# PCIE0_DAT register map
Vendor: Texas Instruments
Registers are 32-bit, read-write, reset 0x0 unless marked. A register's access mark holds for its fields unless they carry their own. Offsets are as the file gives them; [hi:lo] are bit positions.

## PCIE0_DAT (part 5 of 6)
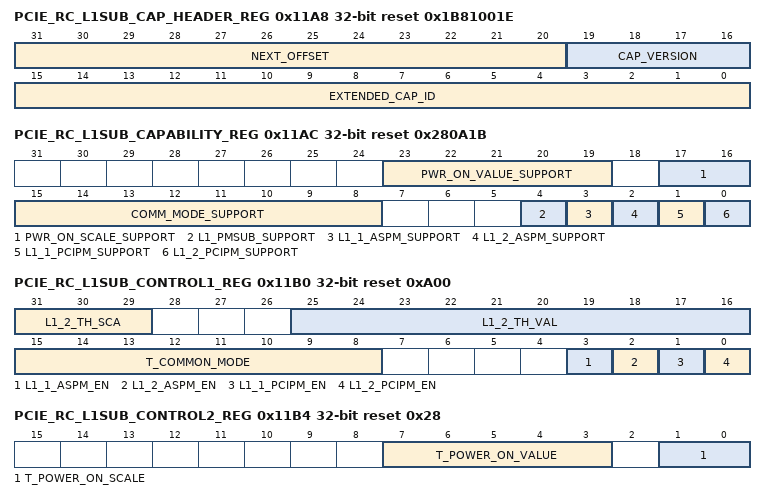
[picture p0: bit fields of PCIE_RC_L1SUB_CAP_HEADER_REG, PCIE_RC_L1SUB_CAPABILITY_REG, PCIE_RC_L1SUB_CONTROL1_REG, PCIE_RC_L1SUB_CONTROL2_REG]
0x11A8 PCIE_RC_L1SUB_CAP_HEADER_REG ro reset 0x1B81001E — L1 Substates Extended Capability Header. For a description of this standard PCIe register, see the PCI Express Specification.
  [31:20] NEXT_OFFSET — Next Capability Offset For a description of this standard PCIe register field, see the PCI Express Specification Note: The access attributes of this field are as follows: - Dbi: if [DBI_RO_WR_EN == 1] then R/W[sticky] else R[sticky] Note: This register field is sticky
  [19:16] CAP_VERSION — Capability Version For a description of this standard PCIe register field, see the PCI Express Specification Note: The access attributes of this field are as follows: - Dbi: if [DBI_RO_WR_EN == 1] then R/W[sticky] else R[sticky] Note: This register field is sticky
  [15:0] EXTENDED_CAP_ID — L1SUB Extended Capability ID For a description of this standard PCIe register field, see the PCI Express Specification Note: The access attributes of this field are as follows: - Dbi: if [DBI_RO_WR_EN == 1] then R/W[sticky] else R[sticky] Note: This register field is sticky
0x11AC PCIE_RC_L1SUB_CAPABILITY_REG access per field reset 0x280A1B — L1 Substates Capability Register. For a description of this standard PCIe register, see the PCI Express Specification.
  [23:19] PWR_ON_VALUE_SUPPORT rw — Port T Power On Value For a description of this standard PCIe register field, see the PCI Express Specification Note: The access attributes of this field are as follows: - Dbi: R/W
  [17:16] PWR_ON_SCALE_SUPPORT rw — Port T Power On Scale For a description of this standard PCIe register field, see the PCI Express Specification Note: The access attributes of this field are as follows: - Dbi: R/W
  [15:8] COMM_MODE_SUPPORT rw — Port Common Mode Restore Time For a description of this standard PCIe register field, see the PCI Express Specification Note: The access attributes of this field are as follows: - Dbi: R/W
  [4] L1_PMSUB_SUPPORT rw — L1 PM Substates ECN Supported For a description of this standard PCIe register field, see the PCI Express Specification Note: The access attributes of this field are as follows: - Dbi: R/W
  [3] L1_1_ASPM_SUPPORT rw — ASPM L11 Supported For a description of this standard PCIe register field, see the PCI Express Specification Note: The access attributes of this field are as follows: - Dbi: R/W
  [2] L1_2_ASPM_SUPPORT rw — ASPM L12 Supported For a description of this standard PCIe register field, see the PCI Express Specification Note: The access attributes of this field are as follows: - Dbi: R/W
  [1] L1_1_PCIPM_SUPPORT rw — PCI-PM L11 Supported For a description of this standard PCIe register field, see the PCI Express Specification Note: The access attributes of this field are as follows: - Dbi: R/W
  [0] L1_2_PCIPM_SUPPORT rw — PCI-PM L12 Supported For a description of this standard PCIe register field, see the PCI Express Specification Note: The access attributes of this field are as follows: - Dbi: R/W
0x11B0 PCIE_RC_L1SUB_CONTROL1_REG access per field reset 0xA00 — L1 Substates Control 1 Register. For a description of this standard PCIe register, see the PCI Express Specification.
  [31:29] L1_2_TH_SCA rw — LTR L12 Threshold Scale For a description of this standard PCIe register field, see the PCI Express Specification
  [25:16] L1_2_TH_VAL rw — LTR L12 Threshold Value For a description of this standard PCIe register field, see the PCI Express Specification
  [15:8] T_COMMON_MODE rw — Common Mode Restore Time For a description of this standard PCIe register field, see the PCI Express Specification Note: The access attributes of this field are as follows: - Dbi: R/W
  [3] L1_1_ASPM_EN rw — ASPM L11 Enable For a description of this standard PCIe register field, see the PCI Express Specification
  [2] L1_2_ASPM_EN rw — ASPM L12 Enable For a description of this standard PCIe register field, see the PCI Express Specification
  [1] L1_1_PCIPM_EN rw — PCI-PM L11 Enable For a description of this standard PCIe register field, see the PCI Express Specification
  [0] L1_2_PCIPM_EN rw — PCI-PM L12 Enable For a description of this standard PCIe register field, see the PCI Express Specification
0x11B4 PCIE_RC_L1SUB_CONTROL2_REG access per field reset 0x28 — L1 Substates Control 2 Register. For a description of this standard PCIe register, see the PCI Express Specification.
  [7:3] T_POWER_ON_VALUE rw — T Power On Value For a description of this standard PCIe register field, see the PCI Express Specification
  [1:0] T_POWER_ON_SCALE rw — T Power On Scale For a description of this standard PCIe register field, see the PCI Express Specification
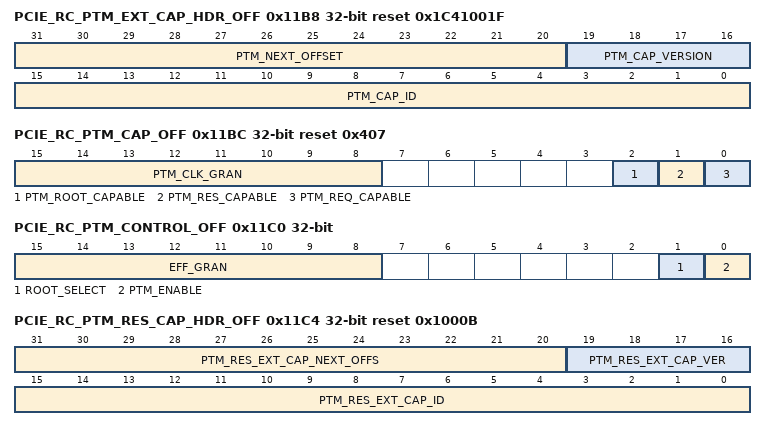
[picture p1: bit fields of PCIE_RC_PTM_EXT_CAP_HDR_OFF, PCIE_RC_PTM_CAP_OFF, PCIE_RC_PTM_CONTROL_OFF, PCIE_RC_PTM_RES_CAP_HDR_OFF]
0x11B8 PCIE_RC_PTM_EXT_CAP_HDR_OFF ro reset 0x1C41001F — Precision Time Measurement Capability Header. For a description of this standard PCIe register, see the PCI Express Specification.
  [31:20] PTM_NEXT_OFFSET — Precision Time Measurement PCI Express Extended Capability Next Offset For a description of this standard PCIe register, see the PCI Express Specification Note: The access attributes of this field are as follows: - Dbi: if [DBI_RO_WR_EN == 1] then R/W[sticky] else R[sticky] Note: This register field is sticky
  [19:16] PTM_CAP_VERSION — Precision Time Measurement PCI Express Extended Capability Version For a description of this standard PCIe register, see the PCI Express Specification Note: The access attributes of this field are as follows: - Dbi: if [DBI_RO_WR_EN == 1] then R/W[sticky] else R[sticky] Note: This register field is sticky
  [15:0] PTM_CAP_ID — Precision Time Measurement PCI Express Extended Capability ID For a description of this standard PCIe register, see the PCI Express Specification Note: The access attributes of this field are as follows: - Dbi: if [DBI_RO_WR_EN == 1] then R/W[sticky] else R[sticky] Note: This register field is sticky
0x11BC PCIE_RC_PTM_CAP_OFF ro reset 0x407 — PTM Capability Register. For a description of this standard PCIe register, see the PCI Express Specification.
  [15:8] PTM_CLK_GRAN — PTM Local Clock Granularity For a description of this standard PCIe register, see the PCI Express Specification Note: The access attributes of this field are as follows: - Dbi: if [DBI_RO_WR_EN == 1] then R/W[sticky] else R[sticky]
  [2] PTM_ROOT_CAPABLE — PTM Root Capable For a description of this standard PCIe register, see the PCI Express Specification Note: The access attributes of this field are as follows: - Dbi: if [DBI_RO_WR_EN == 1] then R/W[sticky] else R[sticky] Note: This register field is sticky
  [1] PTM_RES_CAPABLE — PTM Responder Capable For a description of this standard PCIe register, see the PCI Express Specification Note: The access attributes of this field are as follows: - Dbi: if [DBI_RO_WR_EN == 1] then R/W[sticky] else R[sticky] Note: This register field is sticky
  [0] PTM_REQ_CAPABLE — PTM Requester Capable For a description of this standard PCIe register, see the PCI Express Specification Note: The access attributes of this field are as follows: - Dbi: if [DBI_RO_WR_EN == 1] then R/W[sticky] else R[sticky] Note: This register field is sticky
0x11C0 PCIE_RC_PTM_CONTROL_OFF access per field — PTM Control Register. For a description of this standard PCIe register, see the PCI Express Specification.
  [15:8] EFF_GRAN ro — PTM Effective Granularity For a description of this standard PCIe register, see the PCI Express Specification Note: The access attributes of this field are as follows: - Dbi: HWINIT
  [1] ROOT_SELECT ro — PTM Root Select When set this Time Source is the PTM Root For a description of this standard PCIe register, see the PCI Express Specification Note: The access attributes of this field are as follows: - Dbi: HWINIT
  [0] PTM_ENABLE rw — PTM Enable When set, this function is permitted to participate in the PTM mechanism For a description of this standard PCIe register, see the PCI Express Specification
0x11C4 PCIE_RC_PTM_RES_CAP_HDR_OFF ro reset 0x1000B — Precision Time Measurement Responder Capability Header (VSEC).
  [31:20] PTM_RES_EXT_CAP_NEXT_OFFS — Precision Time Measurement Responder VSEC Next Pointer Note: The access attributes of this field are as follows: - Dbi: if [DBI_RO_WR_EN == 1] then R/W[sticky] else R[sticky] Note: This register field is sticky
  [19:16] PTM_RES_EXT_CAP_VER — Precision Time Measurement Responder VSEC Version Note: The access attributes of this field are as follows: - Dbi: if [DBI_RO_WR_EN == 1] then R/W[sticky] else R[sticky] Note: This register field is sticky
  [15:0] PTM_RES_EXT_CAP_ID — Precision Time Measurement Responder VSEC ID Note: The access attributes of this field are as follows: - Dbi: if [DBI_RO_WR_EN == 1] then R/W[sticky] else R[sticky] Note: This register field is sticky
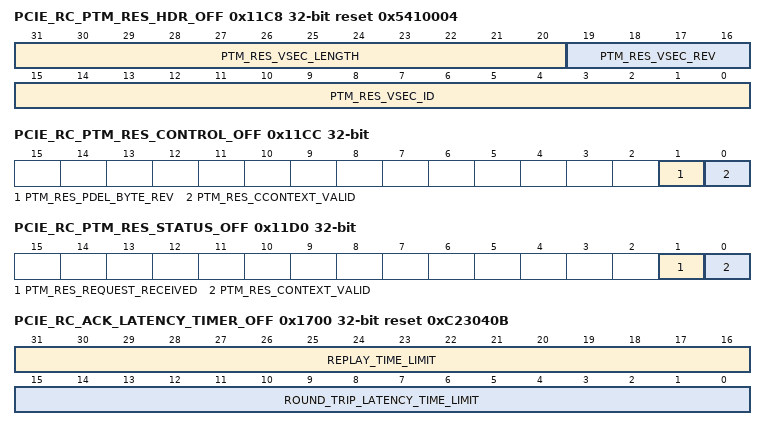
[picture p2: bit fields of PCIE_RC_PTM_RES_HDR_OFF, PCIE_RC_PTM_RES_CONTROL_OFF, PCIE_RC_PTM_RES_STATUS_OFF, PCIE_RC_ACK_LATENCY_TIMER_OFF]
0x11C8 PCIE_RC_PTM_RES_HDR_OFF ro reset 0x5410004 — Precision Time Measurement Responder Vendor Specific Header. .
  [31:20] PTM_RES_VSEC_LENGTH — PTM Responder VSEC Length Note: The access attributes of this field are as follows: - Dbi: if [DBI_RO_WR_EN == 1] then R/W[sticky] else R[sticky] Note: This register field is sticky
  [19:16] PTM_RES_VSEC_REV — PTM Responder VSEC Revision Note: The access attributes of this field are as follows: - Dbi: if [DBI_RO_WR_EN == 1] then R/W[sticky] else R[sticky] Note: This register field is sticky
  [15:0] PTM_RES_VSEC_ID — PTM Responder VSEC ID Note: The access attributes of this field are as follows: - Dbi: if [DBI_RO_WR_EN == 1] then R/W[sticky] else R[sticky] Note: This register field is sticky
0x11CC PCIE_RC_PTM_RES_CONTROL_OFF access per field — PTM Responder Control Register. .
  [1] PTM_RES_PDEL_BYTE_REV rw — PTM Requester Propagation Delay Byte Reversal - Reverse the order of bytes in the PTM Propagation Delay data word of the PTM ResponseD Message, for compatibility with previous revisions. Note: This register field is sticky.
  [0] PTM_RES_CCONTEXT_VALID ro — PTM Responder Control Context Valid - PTM Local Timing is valid This bit is set over the DBI A speed change or aux_clk_active will set this bit low Note: The access attributes of this field are as follows: - Dbi: if [DBI_RO_WR_EN == 1] then R/W[sticky] else R[sticky] Note: This register field is sticky
0x11D0 PCIE_RC_PTM_RES_STATUS_OFF ro — PTM Responder Status Register. .
  [1] PTM_RES_REQUEST_RECEIVED — PTM 1st Request Received - PTM Responder has received the first PTM Request Message Upon receipt of a second PTM Request Message a ResponseD message with timing information will be sent from the Responder, if the context is valid If the context is invalid a Response message will be sent instead Note: This register field is sticky
  [0] PTM_RES_CONTEXT_VALID — PTM Responder Status Context Valid - PTM Local Timing Context is Valid Value set from upstream port Requester in a Switch Shadows the same in the control register in all other products Note: This register field is sticky
0x11D4 PCIE_RC_PTM_RES_LOCAL_LSB_OFF ro — PTM Responder Local Clock LSB. .
  [31:0] PTM_RES_LOCAL_LSB — PTM Responder Local Clock LSB - Lower 32 bits of local timer value Note: The access attributes of this field are as follows: - Dbi: if [DBI_RO_WR_EN == 1] then R/W[sticky] else R[sticky] Note: This register field is sticky
0x11D8 PCIE_RC_PTM_RES_LOCAL_MSB_OFF ro — PTM Responder Local Clock MSB. .
  [31:0] PTM_RES_LOCAL_MSB — PTM Responder Local Clock MSB - Upper 32 bits of local timer value Note: The access attributes of this field are as follows: - Dbi: if [DBI_RO_WR_EN == 1] then R/W[sticky] else R[sticky] Note: This register field is sticky
0x11DC PCIE_RC_PTM_RES_T2_LSB_OFF ro — PTM Responder T2 Timestamp LSB. .
  [31:0] PTM_RES_T2_LSB — PTM Responder T2 Timestamp LSB - Lower 32 bits of the T2 Timestamp value Note: This register field is sticky
0x11E0 PCIE_RC_PTM_RES_T2_MSB_OFF ro — PTM Responder T2 Timestamp MSB. .
  [31:0] PTM_RES_T2_MSB — PTM Responder T2 Timestamp MSB - Upper 32 bits of the T2 Timestamp value Note: This register field is sticky
0x11E4 PCIE_RC_PTM_RES_T2P_LSB_OFF ro — PTM Responder T2 Previous Timestamp LSB. .
  [31:0] PTM_RES_T2P_LSB — PTM Responder T2 Previous Timestamp LSB - Lower 32 bits of the previously stored T2 Timestamp value Note: This register field is sticky
0x11E8 PCIE_RC_PTM_RES_T2P_MSB_OFF ro — PTM Responder T2 Previous Timestamp MSB. .
  [31:0] PTM_RES_T2P_MSB — PTM Responder T2 Previous Timestamp MSB - Upper 32 bits of the previously stored T2 Timestamp value Note: This register field is sticky
0x11EC PCIE_RC_PTM_RES_T3_LSB_OFF ro — PTM Responder T3 Timestamp LSB. .
  [31:0] PTM_RES_T3_LSB — PTM Responder T3 Timestamp LSB - Lower 32 bits of the T3 Timestamp value Note: This register field is sticky
0x11F0 PCIE_RC_PTM_RES_T3_MSB_OFF ro — PTM Responder T3 Timestamp MSB. .
  [31:0] PTM_RES_T3_MSB — PTM Responder T3 Timestamp MSB - Upper 32 bits of the T2 Timestamp value Note: This register field is sticky
0x11F4 PCIE_RC_PTM_RES_T3P_LSB_OFF ro — PTM Responder T3 Previous Timestamp LSB. .
  [31:0] PTM_RES_T3P_LSB — PTM Responder T3 Previous Timestamp LSB - Lower 32 bits of the previously stored T3 Timestamp value Note: This register field is sticky
0x11F8 PCIE_RC_PTM_RES_T3P_MSB_OFF ro — PTM Responder T3 Previous Timestamp MSB. .
  [31:0] PTM_RES_T3P_MSB — PTM Responder T3 Previous Timestamp MSB - Upper 32 bits of the previously stored T3 Timestamp value Note: This register field is sticky
0x11FC PCIE_RC_PTM_RES_TX_LATENCY_OFF access per field reset 0x14 — PTM Responder TX Latency. .
  [11:0] PTM_RES_TX_LATENCY rw — PTM Responder TX Latency - Responder Transmit path latency [12 bit wide] Note: This register field is sticky
0x1200 PCIE_RC_PTM_RES_RX_LATENCY_OFF access per field reset 0x36 — PTM Responder RX Latency. .
  [11:0] PTM_RES_RX_LATENCY rw — PTM Responder RX Latency - Responder Receive path latency [12 bit wide] Note: This register field is sticky
0x1700 PCIE_RC_ACK_LATENCY_TIMER_OFF reset 0xC23040B — Ack Latency Timer and Replay Timer Register.
  [31:16] REPLAY_TIME_LIMIT — Replay Timer Limit The replay timer expires when it reaches this limit The controller initiates a replay upon reception of a NAK or when the replay timer expires You can modify the effective timer limit with the TIMER_MOD_REPLAY_TIMER field of thePCIE_RC_TIMER_CTRL_MAX_FUNC_NUM_OFF register After reset, the controller updates the default according to the Negotiated Link Width, Max_Payload_Size, and speed The value is determined from Tables 3-4, 3-5, and 3-6 of the PCIe 30 specification If there is a change in the payload size or link speed, the controller will override any value that you have written to this register field, and reset the field back to the specification-defined value It will not change the value in the TIMER_MOD_REPLAY_TIMER field of the PCIE_RC_TIMER_CTRL_MAX_FUNC_NUM_OFF register
  [15:0] ROUND_TRIP_LATENCY_TIME_LIMIT — Ack Latency Timer Limit The Ack latency timer expires when it reaches this limit You can modify the effective timer limit with the TIMER_MOD_ACK_NAK field of thePCIE_RC_TIMER_CTRL_MAX_FUNC_NUM_OFF register After reset, the controller updates the default according to the Negotiated Link Width, Max_Payload_Size, and speed The value is determined from Tables 3-7, 3-8, and 3-9 of the PCIe 30 specification The limit must reflect the round trip latency from requester to completer If there is a change in the payload size or link width, the controller will override any value that you have written to this register field, and reset the field back to the specification-defined value It will not change the value in the TIMER_MOD_ACK_NAK field of the PCIE_RC_TIMER_CTRL_MAX_FUNC_NUM_OFF register
0x1704 PCIE_RC_VENDOR_SPEC_DLLP_OFF reset 0xFFFFFFFF — Vendor Specific DLLP Register.
  [31:0] VENDOR_SPEC_DLLP — Vendor Specific DLLP Register Used to send a specific PCI Express DLLP Your application writes the 8-bit DLLP Type and 24-bits of Payload data into this register, then sets the field VENDOR_SPECIFIC_DLLP_REQ of
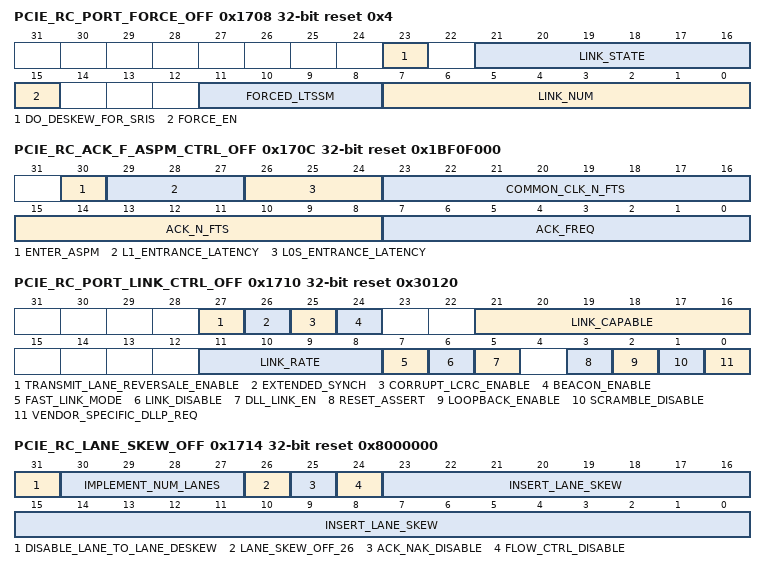
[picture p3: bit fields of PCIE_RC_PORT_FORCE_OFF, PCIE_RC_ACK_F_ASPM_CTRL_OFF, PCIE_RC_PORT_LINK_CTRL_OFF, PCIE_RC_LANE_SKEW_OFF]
0x1708 PCIE_RC_PORT_FORCE_OFF access not given reset 0x4 — Port Force Link Register.
  [23] DO_DESKEW_FOR_SRIS rw — Use the transitions from TS2 to Logical Idle Symbol, SKP OS to Logical Idle Symbol, and FTS Sequence to SKP OS to do deskew for SRIS instead of using received SKP OS if DO_DESKEW_FOR_SRIS is set to 1 Note: This register field is sticky
  [21:16] LINK_STATE rw — Forced LTSSM State The LTSSM state that the controller is forced to when you set the FORCE_EN bit [Force Link] LTSSM state encoding is defined by the lts_state variable in workspace/src/Layer1/smlh_ltssmv Note: This register field is sticky
  [15] FORCE_EN — Force Link The controller supports a testing and debug capability to allow your software to force the LTSSM state machine into a specific state, and to force the controller to transmit a specific Link Command Asserting this bit triggers the following actions: - Forces the LTSSM to the state specified by the Forced LTSSM State field - Forces the controller to transmit the command specified by the Forced Link Command field This is a self-clearing register field Reading from this register field always returns a '0' (access RW1C)
  [11:8] FORCED_LTSSM rw — Forced Link Command The link command that the controller is forced to transmit when you set FORCE_EN bit [Force Link] Link command encoding is defined by the ltssm_cmd variable in workspace/src/Layer1/smlh_ltssmv Note: This register field is sticky
  [7:0] LINK_NUM rw — Link Number Not used for endpoint Not used for M-PCIe Note: This register field is sticky
0x170C PCIE_RC_ACK_F_ASPM_CTRL_OFF access per field reset 0x1BF0F000 — Ack Frequency and L0-L1 ASPM Control Register.
  [30] ENTER_ASPM rw — ASPM L1 Entry Control - 1: Core enters ASPM L1 after a period in which it has been idle - 0: Core enters ASPM L1 only after idle period during which both receive and transmit are in L0s Note: This register field is sticky
  [29:27] L1_ENTRANCE_LATENCY rw — L1 Entrance Latency Value range is: - 000: 1 us - 001: 2 us - 010: 4 us - 011: 8 us - 100: 16 us - 101: 32 us - 110 or 111: 64 us Note: Programming this timer with a value greater that 32us has no effect unless extended sync is used, or all of the credits are infinite Note: This register field is sticky
  [26:24] L0S_ENTRANCE_LATENCY rw — L0s Entrance Latency Values correspond to: - 000: 1 us - 001: 2 us - 010: 3 us - 011: 4 us - 100: 5 us - 101: 6 us - 110 or 111: 7 us This field is applicable to STALL while in L0 for M-PCIe Note: This register field is sticky
  [23:16] COMMON_CLK_N_FTS ro — Common Clock N_FTS This is the N_FTS when common clock is used The number of Fast Training Sequence ordered sets to be transmitted when transitioning from L0s to L0 The maximum number of FTS ordered-sets that a component can request is 255 This field is only writable [sticky] when all of the following configuration parameter equations are true: - CX_NFTS !=CX_COMM_NFTS - DEFAULT_L0S_EXIT_LATENCY !=DEFAULT_COMM_L0S_EXIT_LATENCY - DEFAULT_L1_EXIT_LATENCY !=DEFAULT_COMM_L1_EXIT_LATENCY The controller does not support a value of zero a value of zero can cause the LTSSM to go into the recovery state when exiting from L0s This field is reserved [fixed to '0'] for M-PCIe Note: The access attributes of this field are as follows: - Dbi: R
  [15:8] ACK_N_FTS rw — N_FTS The number of Fast Training Sequence ordered sets to be transmitted when transitioning from L0s to L0 The maximum number of FTS ordered-sets that a component can request is 255 The controller does not support a value of zero a value of zero can cause the LTSSM to go into the recovery state when exiting from L0s This field is reserved [fixed to '0'] for M-PCIe Note: This register field is sticky
  [7:0] ACK_FREQ rw — Ack Frequency The controller accumulates the number of pending ACKs specified here [up to 255] before sending an ACK DLLP - 0: Indicates that this Ack frequency control feature is turned off The controller schedules a low-priority ACK DLLP for every TLP that it receives - 1- 255: Indicates that the controller will schedule a high-priority ACK after receiving this number of TLPs It might schedule the ACK before receiving this number of TLPs, but never later For a typical system, you do not have to modify the default setting Note: This register field is sticky
0x1710 PCIE_RC_PORT_LINK_CTRL_OFF access not given reset 0x30120 — Port Link Control Register.
  [27] TRANSMIT_LANE_REVERSALE_ENABLE rw — TRANSMIT_LANE_REVERSALE_ENABLE is an internally reserved field Do not use Note: This register field is sticky
  [26] EXTENDED_SYNCH rw — EXTENDED_SYNCH is an internally reserved field Do not use Note: This register field is sticky
  [25] CORRUPT_LCRC_ENABLE rw — CORRUPT_LCRC_ENABLE is an internally reserved field Do not use Note: This register field is sticky
  [24] BEACON_ENABLE rw — BEACON_ENABLE is an internally reserved field Do not use Note: This register field is sticky
  [21:16] LINK_CAPABLE rw — Link Mode Enable Sets the number of lanes in the link that you want to connect to the link partner When you have unused lanes in your system, then you must change the value in this register to reflect the number of lanes You must also change the value in the 'Predetermined Number of Lanes' field of the 'Link Width and Speed Change Control Register' - 000001: x 1 - 000011: x 2 - 000111: x 4 - 001111: x 8 - 011111: x 16 - 111111: x32 [not supported] This field is reserved [fixed to '0'] for M-PCIe Note: This register field is sticky
  [11:8] LINK_RATE rw — LINK_RATE is an internally reserved field Do not use Note: This register field is sticky
  [7] FAST_LINK_MODE rw — Fast Link Mode Sets all internal LTSSM millisecond timers to Fast Mode for speeding up simulation Forces the LTSSM training [link initialization] to use shorter time-outs and to link up faster The default scaling factor can be changed using the DEFAULT_FAST_LINK_SCALING_FACTOR parameter or through the FAST_LINK_SCALING_FACTOR field in the
  [6] LINK_DISABLE rw — LINK_DISABLE is an internally reserved field Do not use Note: This register field is sticky
  [5] DLL_LINK_EN rw — DLL Link Enable Enables link initialization When DLL Link Enable =0, the controller does not transmit InitFC DLLPs and does not establish a link Note: This register field is sticky
  [3] RESET_ASSERT rw — Reset Assert Triggers a recovery and forces the LTSSM to the hot reset state [downstream port only] Note: This register field is sticky
  [2] LOOPBACK_ENABLE rw — Loopback Enable Turns on loopback For M-PCIe, to force the master to enter Digital Loopback mode, you must set this field to '1' during Configurationstart state[initial discovery/configuration] M-PCIe doesn't support loopback mode from L0 state - only from Configurationstart Note: This register field is sticky
  [1] SCRAMBLE_DISABLE rw — Scramble Disable Turns off data scrambling Note: This register field is sticky
  [0] VENDOR_SPECIFIC_DLLP_REQ — Vendor Specific DLLP Request When software writes a '1' to this bit, the controller transmits the DLLP contained in the VENDOR_SPEC_DLLP field of (access RW1C)
0x1714 PCIE_RC_LANE_SKEW_OFF reset 0x8000000 — Lane Skew Register.
  [31] DISABLE_LANE_TO_LANE_DESKEW — Disable Lane-to-Lane Deskew Causes the controller to disable the internal Lane-to-Lane deskew logic Note: This register field is sticky
  [30:27] IMPLEMENT_NUM_LANES — Implementation-specific Number of Lanes Set the implementation-specific number of lanes Allowed values are: - 4'b 0000: 1 lane - 4'b 0001: 2 lanes - 4'b 0011: 4 lanes - 4'b 0111: 8 lanes - 4'b 1111: 16 lanes The number of lanes to be used when in Loopback Master The number of lanes programmed must be equal to or less than the valid number of lanes set in LINK_CAPABLE field You must configure this field before initiating Loopback by writing in the LOOPBACK_ENABLE field The controller will transition from LoopbackEntry to LoopbackActive after receiving two consecutive TS1 Ordered Sets with the Loopback bit asserted on the implementation specific number of lanes configured in this field Note: This register field is sticky
  [26] LANE_SKEW_OFF_26 — Reserved Read/Write regsiter for future use Note: This register field is sticky
  [25] ACK_NAK_DISABLE — Ack/Nak Disable Prevents the controller from sending ACK and NAK DLLPs Note: This register field is sticky
  [24] FLOW_CTRL_DISABLE — Flow Control Disable Prevents the controller from sending FC DLLPs Note: This register field is sticky
  [23:0] INSERT_LANE_SKEW — Insert Lane Skew for Transmit [not supported for x16] Optional feature that causes the controller to insert skew between Lanes for test purposes There are three bits per Lane The value is in units of one symbol time For example, the value 010b for a Lane forces a skew of two symbol times for that Lane The maximum skew value for any Lane is 5 symbol times Note: This register field is sticky
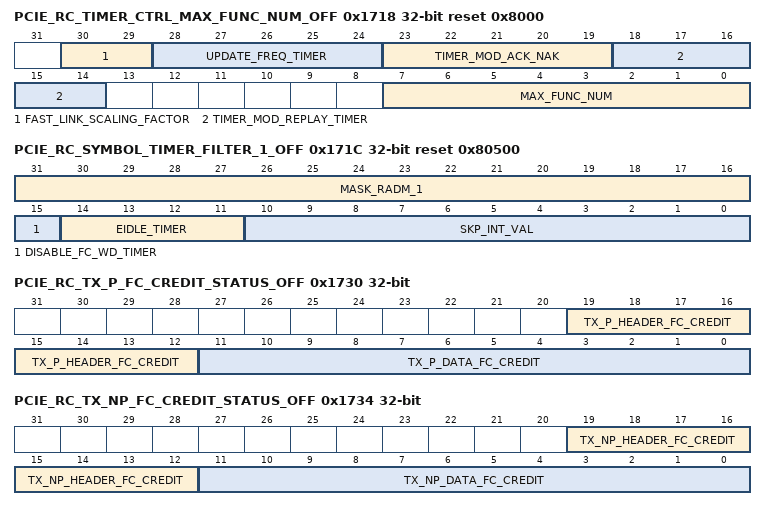
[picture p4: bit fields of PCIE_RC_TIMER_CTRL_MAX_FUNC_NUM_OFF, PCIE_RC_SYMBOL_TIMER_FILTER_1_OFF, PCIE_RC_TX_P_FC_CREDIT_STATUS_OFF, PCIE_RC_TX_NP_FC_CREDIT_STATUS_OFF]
0x1718 PCIE_RC_TIMER_CTRL_MAX_FUNC_NUM_OFF access per field reset 0x8000 — Timer Control and Max Function Number Register.
  [30:29] FAST_LINK_SCALING_FACTOR rw — Fast Link Timer Scaling Factor Sets the scaling factor of LTSSM timer when FAST_LINK_MODE field inPCIE_RC_PORT_LINK_CTRL_OFF is set to '1' - 0: Scaling Factor is 1024 [1ms is 1us] - 1: Scaling Factor is 256 [1ms is 4us] - 2: Scaling Factor is 64 [1ms is 16us] - 3: Scaling Factor is 16 [1ms is 64us] Default is set by the hidden configuration parameter DEFAULT_FAST_LINK_SCALING_FACTOR which defaults to '0' Not used for M-PCIe Note: This register field is sticky
  [28:24] UPDATE_FREQ_TIMER rw — UPDATE_FREQ_TIMER is an internally reserved field Do not use Note: This register field is sticky
  [23:19] TIMER_MOD_ACK_NAK rw — Ack Latency Timer Modifier Increases the timer value for the Ack latency timer in increments of 64 clock cycles A value of '0' represents no modification to the timer value For more details, see the ROUND_TRIP_LATENCY_TIME_LIMIT field of the
  [18:14] TIMER_MOD_REPLAY_TIMER rw — Replay Timer Limit Modifier Increases the time-out value for the replay timer in increments of 64 clock cycles at Gen1 or Gen2 speed, and in increments of 256 clock cycles at Gen3 speed A value of '0' represents no modification to the timer limit For more details, see the REPLAY_TIME_LIMIT field of the
  [7:0] MAX_FUNC_NUM rw — Maximum function number that can be used in a request Configuration requests targeted at function numbers above this value are returned with UR [unsupported request] Note: This register field is sticky
0x171C PCIE_RC_SYMBOL_TIMER_FILTER_1_OFF reset 0x80500 — Symbol Timer Register and Filter Mask 1 Register. The Filter Mask 1 Register modifies the RADM filtering and error handling rules. In each case, '0' applies the associated filtering rule and '1' masks the associated filtering rule.
  [31:16] MASK_RADM_1 — Filter Mask 1. The Filter Mask 1 Register modifies the RADM filtering and error handling rules. In each case, '0' applies the associated filtering rule and '1' masks the associated filtering rule. [31]: CX_FLT_MASK_RC_CFG_DISCARD 0: For RADM RC filter to not allow CFG transaction being received 1: For RADM RC filter to allow CFG transaction being received [30]: CX_FLT_MASK_RC_IO_DISCARD 0: For RADM RC filter to not allow IO transaction being received 1: For RADM RC filter to allow IO transaction being received [29]: CX_FLT_MASK_MSG_DROP 0: Drop MSG TLP [except for Vendor MSG]. Send decoded message on the SII. 1: Do not Drop MSG [except for Vendor MSG]. Send message TLPs to your application on TRGT1 and send decoded message on the SII. The default for this bit is the inverse of FLT_DROP_MSG. That is, if FLT_DROP_MSG = 1, then the default of this bit is '0' [drop message TLPs]. This bit only controls message TLPs other than Vendor MSGs. Vendor MSGs are controlled by Filter Mask Register 2, bits [1:0]. The controller never passes ATS Invalidate messages to the SII interface regardless of this filter rule setting. The controller passes all ATS Invalidate messages to TRGT1 [or AXI bridge master], as they are too big for the SII. [28]: CX_FLT_MASK_CPL_ECRC_DISCARD Only used when completion queue is advertised with infinite credits and is in store-and-forward mode. 0: Discard completions with ECRC errors 1: Allow completions with ECRC errors to be passed up Reserved field for SW. [27]: CX_FLT_MASK_ECRC_DISCARD 0: Discard TLPs with ECRC errors 1: Allow TLPs with ECRC errors to be passed up [26]: CX_FLT_MASK_CPL_LEN_MATCH 0: Enforce length match for completions; a violation results in cpl_abort, and possibly AER of unexp_cpl_err 1: MASK length match for completions [25]: CX_FLT_MASK_CPL_ATTR_MATCH 0: Enforce attribute match for completions; a violation results in a malformed TLP error, and possibly AER of unexp_cpl_err, cpl_rcvd_ur, cpl_rcvd_ca 1: Mask attribute match for completions [24]: CX_FLT_MASK_CPL_TC_MATCH 0: Enforce Traffic Class match for completions; a violation results in a malformed TLP error, and possibly AER of unexp_cpl_err, cpl_rcvd_ur, cpl_rcvd_ca 1: Mask Traffic Class match for completions [23]: CX_FLT_MASK_CPL_FUNC_MATCH 0: Enforce function match for completions; a violation results in cpl_abort, and possibly AER of unexp_cpl_err, cpl_rcvd_ur, cpl_rcvd_ca 1: Mask function match for completions [22]: CX_FLT_MASK_CPL_REQID_MATCH 0: Enforce Req Id match for completions; a violation result in cpl_abort, and possibly AER of unexp_cpl_err, cpl_rcvd_ur, cpl_rcvd_ca 1: Mask Req Id match for completions [21]: CX_FLT_MASK_CPL_TAGERR_MATCH 0: Enforce Tag Error Rules for completions; a violation result in cpl_abort, and possibly AER of unexp_cpl_err, cpl_rcvd_ur, cpl_rcvd_cа 1: Mask Tag Error Rules for completions [20]: CX_FLT_MASK_LOCKED_RD_AS_UR 0: Treat locked Read TLPs as UR for EP; Supported for RC 1: Treat locked Read TLPs as Supported for EP; UR for RC [19]: CX_FLT_MASK_CFG_TYPE1_RE_AS_UR 0: Treat CFG type1 TLPs as UR for EP; Supported for RC 1: Treat CFG type1 TLPs as Supported for EP; UR for RC When CX_SRIOV_ENABLE is set then this bit is set to allow the filter to process Type 1 Config requests, if the EP consumes more than one bus number. [18]: CX_FLT_MASK_UR_OUTSIDE_BAR 0: Treat out-of-bar TLPs as UR 1: Do not treat out-of-bar TLPs as UR [17]: CX_FLT_MASK_UR_POIS 0: Treat poisoned request TLPs as UR 1: Do not treat poisoned request TLPs as UR The native controller always passes poisoned completions to your application except when you are using the DMA read channel. [16]: CX_FLT_MASK_UR_FUNC_MISMATCH 0: Treat Function MisMatched TLPs as UR 1: Do not treat Function MisMatched TLPs as UR Note: This register field is sticky.
  [15] DISABLE_FC_WD_TIMER — Disable FC Watchdog Timer. Note: This register field is sticky.
  [14:11] EIDLE_TIMER — EIDLE_TIMER is an internally reserved field. Do not use. Note: This register field is sticky.
  [10:0] SKP_INT_VAL — SKP Interval Value. The number of symbol times to wait between transmitting SKP ordered sets. Note that the controller actually waits the number of symbol times in this register plus 1 between transmitting SKP ordered sets. Your application must program this register accordingly. For example, if 1536 were programmed into this register [in a 250 MHz controller], then the controller actually transmits SKP ordered sets once every 1537 symbol times. The value programmed to this register is actually clock ticks and not symbol times. In a 125 MHz controller, programming the value programmed to this register should be scaled down by a factor of 2 [because one clock tick = two symbol times in this case]. Note: This value is not used at Gen3 speed. The skip interval is hardcoded to 370 blocks For M-PCIe configurations, if the 2K_PPM_DISABLED field in the M-PCIe Configuration Attribute is changed, then this field is changed automatically as follows: 2K_PPM_DISABLED = 1: 1280/CX_NB 2K_PPM_DISABLED = 0: 228/CX_NB You need to set this field again, if necessary, when 2K_PPM_DISABLED is changed. Note: This register field is sticky.
0x1720 PCIE_RC_FILTER_MASK_2_OFF — Filter Mask 2 Register. This register modifies the RADM filtering and error handling rules. In each case, '0' applies the associated filtering rule and '1' masks the associated filtering rule.
  [31:0] MASK_RADM_2 — Filter Mask 2. This field modifies the RADM filtering and error handling rules. In each case, '0' applies the associated filtering rule and '1' masks the associated filtering rule.
0x1724 PCIE_RC_AMBA_MUL_OB_DECOMP_NP_SUB_REQ_CTRL_OFF access per field reset 0x1 — AMBA Multiple Outbound Decomposed NP SubRequests Control Register.
  [0] OB_RD_SPLIT_BURST_EN rw — Enable AMBA Multiple Outbound Decomposed NP SubRequests This bit when set to '0' disables the possibility of having multiple outstanding non-posted requests that were derived from decomposition of an outbound AMBA request You should not clear this register unless your application master is requesting an amount of read data greater than Max_Read_Request_Size, and the remote device [or switch] is reordering completions that have different tags Note: The access attributes of this field are as follows: - Dbi: R/W [sticky] Note: This register field is sticky
0x1728 PCIE_RC_PL_DEBUG0_OFF ro — Debug Register 0
  [31:0] DEB_REG_0 — This field contains bits [31:0] of the cxpl_debug_info[63:0] bus. The value on cxpl_debug_info[31:0] is as follows:
0x172C PCIE_RC_PL_DEBUG1_OFF ro — Debug Register 1
  [31:0] DEB_REG_1 — This field contains bits [63:32] of the cxpl_debug_info[63:0] bus. The value on cxpl_debug_info[63:32] is as follows:
0x1730 PCIE_RC_TX_P_FC_CREDIT_STATUS_OFF ro — Transmit Posted FC Credit Status
  [19:12] TX_P_HEADER_FC_CREDIT — Transmit Posted Header FC Credits The posted Header credits advertised by the receiver at the other end of the link, updated with each UpdateFC DLLP Default value depends on the number of advertised credits for header and data [12'b0, xtlh_xadm_ph_cdts, xtlh_xadm_pd_cdts] When the number of advertised completion credits [both header and data] are infinite, then the default would be [12'b0, 8'hFF, 12'hFFF]
  [11:0] TX_P_DATA_FC_CREDIT — Transmit Posted Data FC Credits The posted Data credits advertised by the receiver at the other end of the link, updated with each UpdateFC DLLP Default value depends on the number of advertised credits for header and data [12'b0, xtlh_xadm_ph_cdts, xtlh_xadm_pd_cdts] When the number of advertised completion credits [both header and data] are infinite, then the default would be [12'b0, 8'hFF, 12'hFFF]
0x1734 PCIE_RC_TX_NP_FC_CREDIT_STATUS_OFF ro — Transmit Non-Posted FC Credit Status
  [19:12] TX_NP_HEADER_FC_CREDIT — Transmit Non-Posted Header FC Credits The non-posted Header credits advertised by the receiver at the other end of the link, updated with each UpdateFC DLLP Default value depends on the number of advertised credits for header and data [12'b0, xtlh_xadm_nph_cdts, xtlh_xadm_npd_cdts] When the number of advertised completion credits [both header and data] are infinite, then the default would be [12'b0, 8'hFF, 12'hFFF]
  [11:0] TX_NP_DATA_FC_CREDIT — Transmit Non-Posted Data FC Credits The non-posted Data credits advertised by the receiver at the other end of the link, updated with each UpdateFC DLLP Default value depends on the number of advertised credits for header and data [12'b0, xtlh_xadm_nph_cdts, xtlh_xadm_npd_cdts] When the number of advertised completion credits [both header and data] are infinite, then the default would be [12'b0, 8'hFF, 12'hFFF]
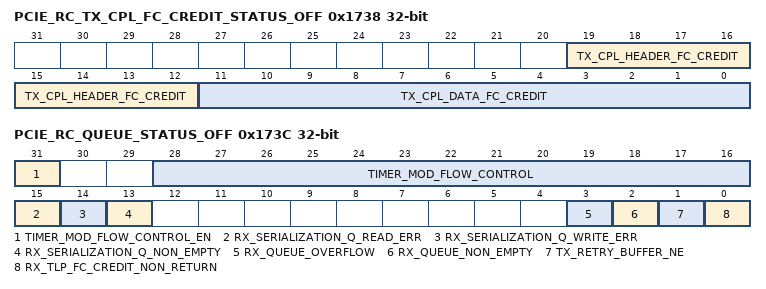
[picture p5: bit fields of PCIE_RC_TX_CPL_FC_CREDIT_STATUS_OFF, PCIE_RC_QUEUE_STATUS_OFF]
0x1738 PCIE_RC_TX_CPL_FC_CREDIT_STATUS_OFF ro — Transmit Completion FC Credit Status
  [19:12] TX_CPL_HEADER_FC_CREDIT — Transmit Completion Header FC Credits The Completion Header credits advertised by the receiver at the other end of the link, updated with each UpdateFC DLLP Default value depends on the number of advertised credits for header and data [12'b0, xtlh_xadm_cplh_cdts, xtlh_xadm_cpld_cdts] When the number of advertised completion credits [both header and data] are infinite, then the default would be [12'b0, 8'hFF, 12'hFFF]
  [11:0] TX_CPL_DATA_FC_CREDIT — Transmit Completion Data FC Credits The Completion Data credits advertised by the receiver at the other end of the link, updated with each UpdateFC DLLP Default value depends on the number of advertised credits for header and data [12'b0, xtlh_xadm_cplh_cdts, xtlh_xadm_cpld_cdts] When the number of advertised completion credits [both header and data] are infinite, then the default would be [12'b0, 8'hFF, 12'hFFF]
0x173C PCIE_RC_QUEUE_STATUS_OFF access not given — Queue Status
  [31] TIMER_MOD_FLOW_CONTROL_EN rw — FC Latency Timer Override Enable When this bit is set, the value from the 'FC Latency Timer Override Value' field in this register will override the FC latency timer value that the controller calculates according to the PCIe specification Note: This register field is sticky
  [28:16] TIMER_MOD_FLOW_CONTROL rw — FC Latency Timer Override Value When you set the 'FC Latency Timer Override Enable' in this register, the value in this field will override the FC latency timer value that the controller calculates according to the PCIe specification Note: This register field is sticky
  [15] RX_SERIALIZATION_Q_READ_ERR — Receive Serialization Read Error Indicates the serialization queue has attempted to read an incorrectly formatted TLP (access RW1C)
  [14] RX_SERIALIZATION_Q_WRITE_ERR — Receive Serialization Queue Write Error Indicates insufficient buffer space available to write to the serialization queue (access RW1C)
  [13] RX_SERIALIZATION_Q_NON_EMPTY ro — Receive Serialization Queue Not Empty Indicates there is data in the serialization queue
  [3] RX_QUEUE_OVERFLOW — Receive Credit Queue Overflow Indicates insufficient buffer space available to write to the P/NP/CPL credit queue (access RW1C)
  [2] RX_QUEUE_NON_EMPTY ro — Receive Credit Queue Not Empty Indicates there is data in one or more of the receive buffers
  [1] TX_RETRY_BUFFER_NE ro — Transmit Retry Buffer Not Empty Indicates that there is data in the transmit retry buffer
  [0] RX_TLP_FC_CREDIT_NON_RETURN ro — Received TLP FC Credits Not Returned Indicates that the controller has received a TLP but has not yet sent an UpdateFC DLLP indicating that the credits for that TLP have been restored by the receiver at the other end of the link
